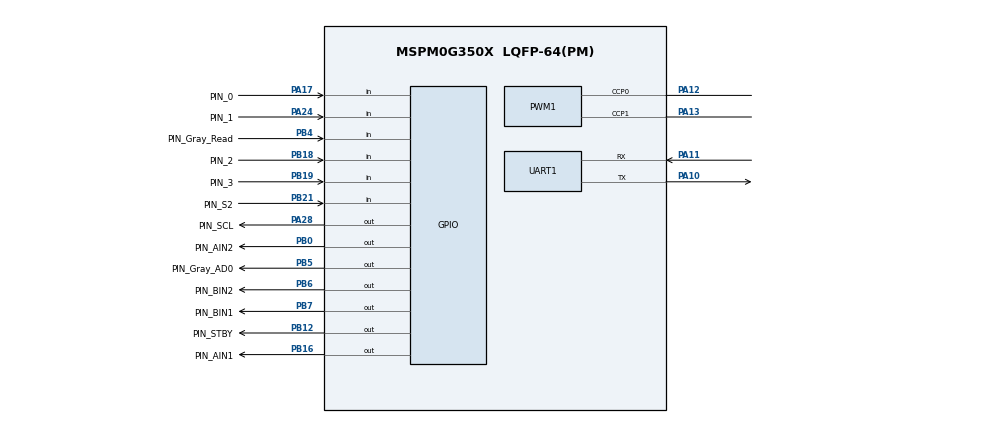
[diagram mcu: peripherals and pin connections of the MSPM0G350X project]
/**
 * @cliArgs --device "MSPM0G350X" --part "Default" --package "LQFP-64(PM)" --product "mspm0_sdk@2.10.00.04"
 * @versions {"tool":"1.26.2+4477"}
 */

/**
 * Import the modules used in this configuration.
 */
const Board  = scripting.addModule("/ti/driverlib/Board");
const GPIO   = scripting.addModule("/ti/driverlib/GPIO", {}, false);
const GPIO1  = GPIO.addInstance();
const GPIO2  = GPIO.addInstance();
const GPIO3  = GPIO.addInstance();
const GPIO4  = GPIO.addInstance();
const GPIO5  = GPIO.addInstance();
const GPIO6  = GPIO.addInstance();
const GPIO7  = GPIO.addInstance();
const GPIO8  = GPIO.addInstance();
const GPIO9  = GPIO.addInstance();
const PWM    = scripting.addModule("/ti/driverlib/PWM", {}, false);
const PWM1   = PWM.addInstance();
const SYSCTL = scripting.addModule("/ti/driverlib/SYSCTL");
const TIMER  = scripting.addModule("/ti/driverlib/TIMER", {}, false);
const TIMER1 = TIMER.addInstance();
const TIMER2 = TIMER.addInstance();
const UART   = scripting.addModule("/ti/driverlib/UART", {}, false);
const UART1  = UART.addInstance();

/**
 * Write custom configuration values to the imported modules.
 */
const divider7       = system.clockTree["PLL_PDIV"];
divider7.divideValue = 8;

const divider9       = system.clockTree["UDIV"];
divider9.divideValue = 2;

const multiplier2         = system.clockTree["PLL_QDIV"];
multiplier2.multiplyValue = 40;

const mux8       = system.clockTree["HSCLKMUX"];
mux8.inputSelect = "HSCLKMUX_SYSPLL0";


GPIO1.$name                         = "GPIO_EncoderA";
GPIO1.port                          = "PORTA";
GPIO1.associatedPins.create(2);
GPIO1.associatedPins[0].$name       = "PIN_0";
GPIO1.associatedPins[0].direction   = "INPUT";
GPIO1.associatedPins[0].interruptEn = true;
GPIO1.associatedPins[0].polarity    = "RISE";
GPIO1.associatedPins[0].pin.$assign = "PA17";
GPIO1.associatedPins[1].$name       = "PIN_1";
GPIO1.associatedPins[1].direction   = "INPUT";
GPIO1.associatedPins[1].interruptEn = true;
GPIO1.associatedPins[1].polarity    = "RISE";
GPIO1.associatedPins[1].pin.$assign = "PA24";

GPIO2.$name                         = "GPIO_EncoderB";
GPIO2.port                          = "PORTB";
GPIO2.associatedPins.create(2);
GPIO2.associatedPins[0].direction   = "INPUT";
GPIO2.associatedPins[0].interruptEn = true;
GPIO2.associatedPins[0].polarity    = "RISE";
GPIO2.associatedPins[0].$name       = "PIN_2";
GPIO2.associatedPins[0].pin.$assign = "PB18";
GPIO2.associatedPins[1].direction   = "INPUT";
GPIO2.associatedPins[1].interruptEn = true;
GPIO2.associatedPins[1].polarity    = "RISE";
GPIO2.associatedPins[1].$name       = "PIN_3";
GPIO2.associatedPins[1].pin.$assign = "PB19";

GPIO3.$name                         = "GPIO_IN";
GPIO3.associatedPins.create(4);
GPIO3.associatedPins[0].$name       = "PIN_AIN1";
GPIO3.associatedPins[0].pin.$assign = "PB16";
GPIO3.associatedPins[1].$name       = "PIN_AIN2";
GPIO3.associatedPins[1].pin.$assign = "PB0";
GPIO3.associatedPins[2].$name       = "PIN_BIN1";
GPIO3.associatedPins[2].pin.$assign = "PB7";
GPIO3.associatedPins[3].$name       = "PIN_BIN2";
GPIO3.associatedPins[3].pin.$assign = "PB6";

GPIO4.$name                          = "GPIO_Gray";
GPIO4.associatedPins.create(4);
GPIO4.associatedPins[0].direction    = "INPUT";
GPIO4.associatedPins[0].$name        = "PIN_Gray_Read";
GPIO4.associatedPins[0].pin.$assign  = "PB4";
GPIO4.associatedPins[1].$name        = "PIN_Gray_AD0";
GPIO4.associatedPins[1].assignedPin  = "5";
GPIO4.associatedPins[1].assignedPort = "PORTB";
GPIO4.associatedPins[1].pin.$assign  = "PB5";
GPIO4.associatedPins[2].$name        = "PIN_Gray_AD1";
GPIO4.associatedPins[2].assignedPort = "PORTA";
GPIO4.associatedPins[2].assignedPin  = "8";
GPIO4.associatedPins[3].$name        = "PIN_Gray_AD2";
GPIO4.associatedPins[3].assignedPort = "PORTA";
GPIO4.associatedPins[3].assignedPin  = "9";

GPIO5.$name                          = "GPIO_OLED";
GPIO5.associatedPins.create(2);
GPIO5.associatedPins[0].$name        = "PIN_SCL";
GPIO5.associatedPins[0].assignedPort = "PORTA";
GPIO5.associatedPins[0].assignedPin  = "28";
GPIO5.associatedPins[0].pin.$assign  = "PA28";
GPIO5.associatedPins[1].$name        = "PIN_SDA";
GPIO5.associatedPins[1].assignedPort = "PORTA";
GPIO5.associatedPins[1].assignedPin  = "31";

GPIO6.$name                              = "GPIO_Key";
GPIO6.associatedPins.create(2);
GPIO6.associatedPins[0].$name            = "PIN_S2";
GPIO6.associatedPins[0].direction        = "INPUT";
GPIO6.associatedPins[0].internalResistor = "PULL_UP";
GPIO6.associatedPins[0].pin.$assign      = "PB21";
GPIO6.associatedPins[1].$name            = "PIN_S1";
GPIO6.associatedPins[1].direction        = "INPUT";
GPIO6.associatedPins[1].internalResistor = "PULL_UP";
GPIO6.associatedPins[1].assignedPort     = "PORTA";

GPIO7.$name                   = "GPIO_LED";
GPIO7.associatedPins[0].$name = "PIN_LED";

GPIO8.$name                         = "GPIO_STBY";
GPIO8.associatedPins[0].$name       = "PIN_STBY";
GPIO8.associatedPins[0].pin.$assign = "PB12";

GPIO9.$name                          = "MPU6050_I2C";
GPIO9.associatedPins.create(2);
GPIO9.associatedPins[0].$name        = "SCL";
GPIO9.associatedPins[0].ioStructure  = "OD";
GPIO9.associatedPins[0].assignedPort = "PORTA";
GPIO9.associatedPins[0].assignedPin  = "1";
GPIO9.associatedPins[0].initialValue = "SET";
GPIO9.associatedPins[1].$name        = "SDA";
GPIO9.associatedPins[1].ioStructure  = "OD";
GPIO9.associatedPins[1].assignedPort = "PORTA";
GPIO9.associatedPins[1].assignedPin  = "0";
GPIO9.associatedPins[1].initialValue = "SET";

PWM1.$name                      = "PWM_0";
PWM1.timerCount                 = 2500;
PWM1.peripheral.ccp0Pin.$assign = "PA12";
PWM1.peripheral.ccp1Pin.$assign = "PA13";
PWM1.PWM_CHANNEL_0.$name        = "ti_driverlib_pwm_PWMTimerCC0";
PWM1.PWM_CHANNEL_1.$name        = "ti_driverlib_pwm_PWMTimerCC1";
PWM1.ccp0PinConfig.$name        = "ti_driverlib_gpio_GPIOPinGeneric0";
PWM1.ccp1PinConfig.$name        = "ti_driverlib_gpio_GPIOPinGeneric1";

SYSCTL.forceDefaultClkConfig = true;
SYSCTL.clockTreeEn           = true;

TIMER1.$name              = "TIMER_Encoder_Read";
TIMER1.timerClkPrescale   = 256;
TIMER1.timerMode          = "PERIODIC";
TIMER1.interrupts         = ["ZERO"];
TIMER1.timerPeriod        = "50ms";
TIMER1.peripheral.$assign = "TIMG6";

TIMER2.$name              = "TIMER_0";
TIMER2.timerPeriod        = "10 ms";
TIMER2.timerClkPrescale   = 256;
TIMER2.timerMode          = "PERIODIC";
TIMER2.interrupts         = ["ZERO"];
TIMER2.peripheral.$assign = "TIMG7";

UART1.$name                    = "UART_0";
UART1.targetBaudRate           = 115200;
UART1.peripheral.rxPin.$assign = "PA11";
UART1.peripheral.txPin.$assign = "PA10";
UART1.txPinConfig.$name        = "ti_driverlib_gpio_GPIOPinGeneric2";
UART1.rxPinConfig.$name        = "ti_driverlib_gpio_GPIOPinGeneric3";

/**
 * Pinmux solution for unlocked pins/peripherals. This ensures that minor changes to the automatic solver in a future
 * version of the tool will not impact the pinmux you originally saw.  These lines can be completely deleted in order to
 * re-solve from scratch.
 */
Board.peripheral.$suggestSolution            = "DEBUGSS";
Board.peripheral.swclkPin.$suggestSolution   = "PA20";
Board.peripheral.swdioPin.$suggestSolution   = "PA19";
GPIO4.associatedPins[2].pin.$suggestSolution = "PA8";
GPIO4.associatedPins[3].pin.$suggestSolution = "PA9";
GPIO5.associatedPins[1].pin.$suggestSolution = "PA31";
GPIO6.associatedPins[1].pin.$suggestSolution = "PA14";
GPIO7.associatedPins[0].pin.$suggestSolution = "PB13";
GPIO9.associatedPins[0].pin.$suggestSolution = "PA1";
GPIO9.associatedPins[1].pin.$suggestSolution = "PA0";
PWM1.peripheral.$suggestSolution             = "TIMG0";
UART1.peripheral.$suggestSolution            = "UART0";
